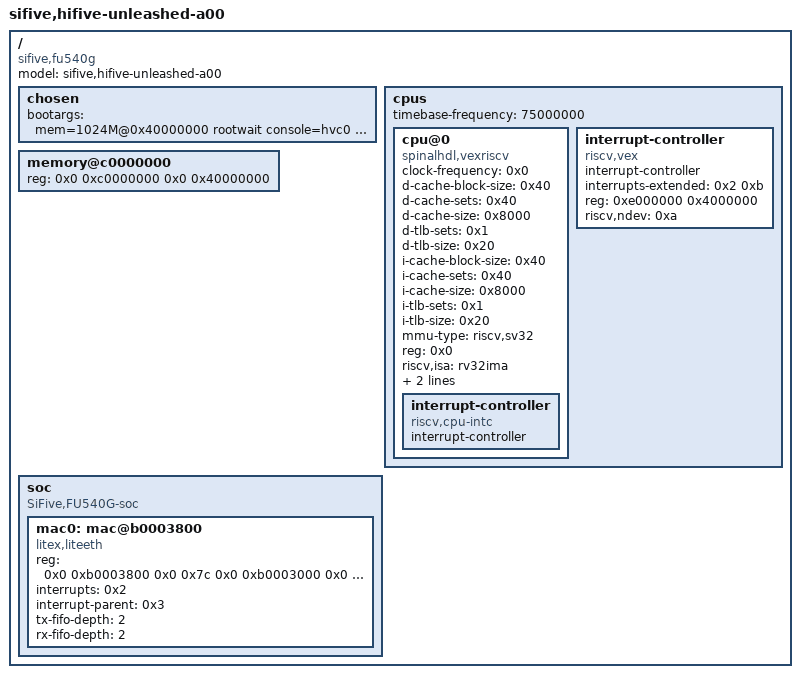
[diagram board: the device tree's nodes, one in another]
/dts-v1/;

/ {
	#address-cells = <0x2>;
	#size-cells = <0x2>;
	compatible = "sifive,fu540g", "sifive,fu500";
	model = "sifive,hifive-unleashed-a00";

	chosen {
		bootargs = "mem=1024M@0x40000000 rootwait console=hvc0 root=/dev/nfs nfsroot=192.168.7.1:/srv/nfsroot,rsize=1024,wsize=1024,nolock,udp,nfsvers=3 ip=192.168.7.100:192.168.7.1:192.168.7.1:255.255.255.0:vexriscv:eth0:none:8.8.8.8 init=/sbin/init swiotlb=32";
		// linux,initrd-start = <0xC0800000>;
		// linux,initrd-end   = <0xC1000000>; // max 8MB ramdisk image
	};

	cpus {
		#address-cells = <0x1>;
		#size-cells = <0x0>;
		timebase-frequency = <75000000>;

		cpu@0 {
			clock-frequency = <0x0>;
			compatible = "spinalhdl,vexriscv", "sifive,rocket0", "riscv";
			d-cache-block-size = <0x40>;
			d-cache-sets = <0x40>;
			d-cache-size = <0x8000>;
			d-tlb-sets = <0x1>;
			d-tlb-size = <0x20>;
			device_type = "cpu";
			i-cache-block-size = <0x40>;
			i-cache-sets = <0x40>;
			i-cache-size = <0x8000>;
			i-tlb-sets = <0x1>;
			i-tlb-size = <0x20>;
			mmu-type = "riscv,sv32";
			reg = <0x0>;
			riscv,isa = "rv32ima";
			sifive,itim = <0x1>;
			status = "okay";
			tlb-split;

			interrupt-controller {
				#interrupt-cells = <0x1>;
				compatible = "riscv,cpu-intc";
				interrupt-controller;
				phandle = <0x2>;
			};
		};

		interrupt-controller {
			#address-cells = <0x0>;
			#interrupt-cells = <0x1>;
			compatible = "riscv,vex";
			interrupt-controller;
			interrupts-extended = <0x2 0xb>;
			reg = <0xe000000 0x4000000>;
			riscv,ndev = <0xa>;
			phandle = <0x3>;
		};
	};

	memory@c0000000 {
		device_type = "memory";
		reg = <0x0 0xc0000000 0x0 0x40000000>;
	};

	soc {
		#address-cells = <0x2>;
		#size-cells = <0x2>;
		compatible = "SiFive,FU540G-soc", "fu500-soc", "sifive-soc", "simple-bus";
		ranges;

		mac0: mac@b0003800 {
			compatible = "litex,liteeth";
			reg = <0x0 0xb0003800 0x0 0x7c
				0x0 0xb0003000 0x0 0x0a
				0x0 0xa0000000 0x0 0x2000>;
			interrupts = <0x2>;
			interrupt-parent = <0x3>;
			tx-fifo-depth = <2>;
			rx-fifo-depth = <2>;
		};
/*
		framebuffer0: framebuffer@f0000000 {
			compatible = "simple-framebuffer";
			reg = <0x0 0xf0000000 0x0 0x12C000>;
			width = <640>;
			height = <480>;
			stride = <2560>;
			format = "a8b8g8r8";
		};
*/

	};

};
